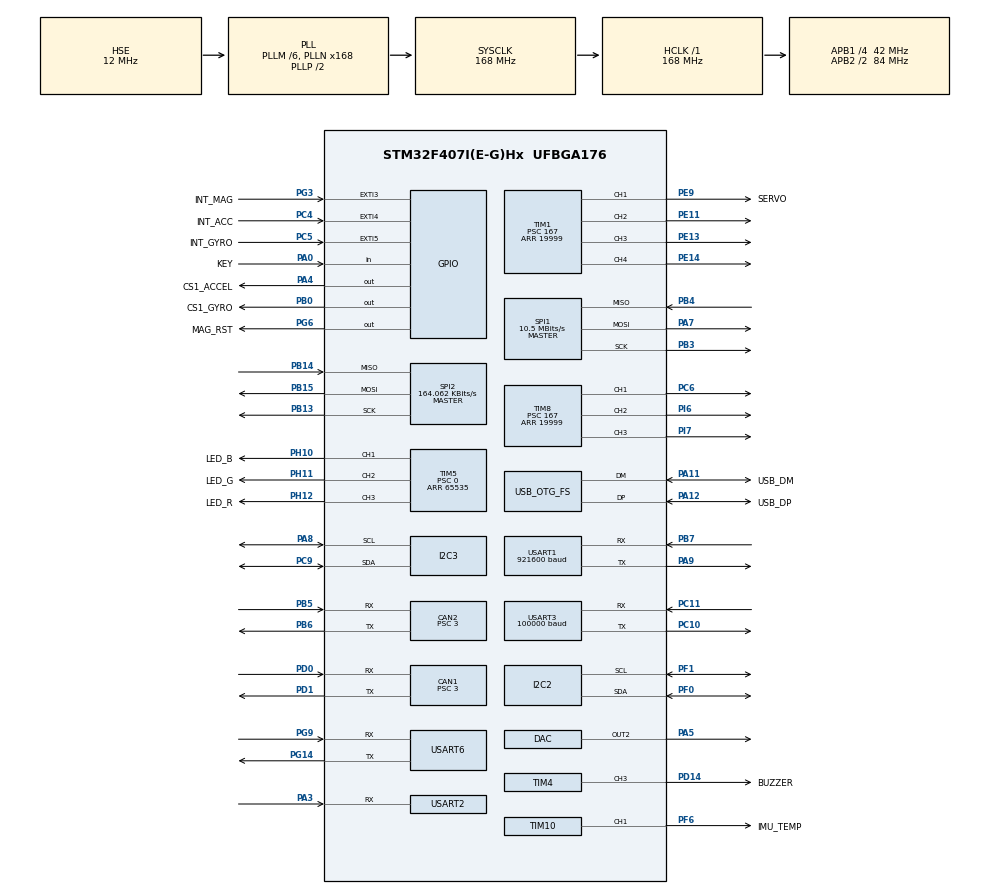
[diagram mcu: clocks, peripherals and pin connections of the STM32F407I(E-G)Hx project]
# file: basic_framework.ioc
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ADC1.Channel-0\#ChannelRegularConversion=ADC_CHANNEL_TEMPSENSOR
ADC1.ClockPrescaler=ADC_CLOCK_SYNC_PCLK_DIV6
ADC1.NbrOfConversionFlag=1
ADC1.Rank-0\#ChannelRegularConversion=1
ADC1.SamplingTime-0\#ChannelRegularConversion=ADC_SAMPLETIME_3CYCLES
ADC1.master=1
CAN1.BS1=CAN_BS1_10TQ
CAN1.BS2=CAN_BS2_3TQ
CAN1.CalculateBaudRate=1000000
CAN1.CalculateTimeBit=1000
CAN1.CalculateTimeQuantum=71.42857142857143
CAN1.NART=ENABLE
CAN1.Prescaler=3
CAN1.TXFP=ENABLE
CAN2.BS1=CAN_BS1_10TQ
CAN2.BS2=CAN_BS2_3TQ
CAN2.CalculateBaudRate=1000000
CAN2.CalculateTimeBit=1000
CAN2.CalculateTimeQuantum=71.42857142857143
CAN2.NART=ENABLE
CAN2.Prescaler=3
CAN2.TXFP=ENABLE
Dma.I2C2_RX.6.Direction=DMA_PERIPH_TO_MEMORY
Dma.I2C2_RX.6.FIFOMode=DMA_FIFOMODE_DISABLE
Dma.I2C2_RX.6.Instance=DMA1_Stream2
Dma.I2C2_RX.6.MemDataAlignment=DMA_MDATAALIGN_BYTE
Dma.I2C2_RX.6.MemInc=DMA_MINC_ENABLE
Dma.I2C2_RX.6.Mode=DMA_NORMAL
Dma.I2C2_RX.6.PeriphDataAlignment=DMA_PDATAALIGN_BYTE
Dma.I2C2_RX.6.PeriphInc=DMA_PINC_DISABLE
Dma.I2C2_RX.6.Priority=DMA_PRIORITY_LOW
Dma.I2C2_TX.7.Direction=DMA_MEMORY_TO_PERIPH
Dma.I2C2_TX.7.FIFOMode=DMA_FIFOMODE_DISABLE
Dma.I2C2_TX.7.Instance=DMA1_Stream7
Dma.I2C2_TX.7.MemDataAlignment=DMA_MDATAALIGN_BYTE
Dma.I2C2_TX.7.MemInc=DMA_MINC_ENABLE
Dma.I2C2_TX.7.Mode=DMA_NORMAL
Dma.I2C2_TX.7.PeriphDataAlignment=DMA_PDATAALIGN_BYTE
Dma.I2C2_TX.7.PeriphInc=DMA_PINC_DISABLE
Dma.I2C2_TX.7.Priority=DMA_PRIORITY_LOW
Dma.Request0=USART6_RX
Dma.Request1=USART6_TX
Dma.Request2=USART1_TX
Dma.Request3=USART1_RX
Dma.Request4=SPI1_RX
Dma.Request5=USART3_RX
Dma.Request6=I2C2_RX
Dma.Request7=I2C2_TX
Dma.Request8=SPI1_TX
Dma.Request9=USART2_RX
Dma.SPI1_RX.4.Direction=DMA_PERIPH_TO_MEMORY
Dma.SPI1_RX.4.FIFOMode=DMA_FIFOMODE_ENABLE
Dma.SPI1_RX.4.FIFOThreshold=DMA_FIFO_THRESHOLD_FULL
Dma.SPI1_RX.4.Instance=DMA2_Stream0
Dma.SPI1_RX.4.MemBurst=DMA_MBURST_SINGLE
Dma.SPI1_RX.4.MemDataAlignment=DMA_MDATAALIGN_BYTE
Dma.SPI1_RX.4.MemInc=DMA_MINC_ENABLE
Dma.SPI1_RX.4.Mode=DMA_NORMAL
Dma.SPI1_RX.4.PeriphBurst=DMA_PBURST_SINGLE
Dma.SPI1_RX.4.PeriphDataAlignment=DMA_PDATAALIGN_BYTE
Dma.SPI1_RX.4.PeriphInc=DMA_PINC_DISABLE
Dma.SPI1_RX.4.Priority=DMA_PRIORITY_HIGH
Dma.SPI1_TX.8.Direction=DMA_MEMORY_TO_PERIPH
Dma.SPI1_TX.8.FIFOMode=DMA_FIFOMODE_DISABLE
Dma.SPI1_TX.8.Instance=DMA2_Stream3
Dma.SPI1_TX.8.MemDataAlignment=DMA_MDATAALIGN_BYTE
Dma.SPI1_TX.8.MemInc=DMA_MINC_ENABLE
Dma.SPI1_TX.8.Mode=DMA_NORMAL
Dma.SPI1_TX.8.PeriphDataAlignment=DMA_PDATAALIGN_BYTE
Dma.SPI1_TX.8.PeriphInc=DMA_PINC_DISABLE
Dma.SPI1_TX.8.Priority=DMA_PRIORITY_HIGH
Dma.USART1_RX.3.Direction=DMA_PERIPH_TO_MEMORY
Dma.USART1_RX.3.FIFOMode=DMA_FIFOMODE_DISABLE
Dma.USART1_RX.3.Instance=DMA2_Stream5
Dma.USART1_RX.3.MemDataAlignment=DMA_MDATAALIGN_BYTE
Dma.USART1_RX.3.MemInc=DMA_MINC_ENABLE
Dma.USART1_RX.3.Mode=DMA_NORMAL
Dma.USART1_RX.3.PeriphDataAlignment=DMA_PDATAALIGN_BYTE
Dma.USART1_RX.3.PeriphInc=DMA_PINC_DISABLE
Dma.USART1_RX.3.Priority=DMA_PRIORITY_VERY_HIGH
Dma.USART1_TX.2.Direction=DMA_MEMORY_TO_PERIPH
Dma.USART1_TX.2.FIFOMode=DMA_FIFOMODE_DISABLE
Dma.USART1_TX.2.Instance=DMA2_Stream7
Dma.USART1_TX.2.MemDataAlignment=DMA_MDATAALIGN_BYTE
Dma.USART1_TX.2.MemInc=DMA_MINC_ENABLE
Dma.USART1_TX.2.Mode=DMA_NORMAL
Dma.USART1_TX.2.PeriphDataAlignment=DMA_PDATAALIGN_BYTE
Dma.USART1_TX.2.PeriphInc=DMA_PINC_DISABLE
Dma.USART1_TX.2.Priority=DMA_PRIORITY_VERY_HIGH
Dma.USART2_RX.9.Direction=DMA_PERIPH_TO_MEMORY
Dma.USART2_RX.9.FIFOMode=DMA_FIFOMODE_DISABLE
Dma.USART2_RX.9.Instance=DMA1_Stream5
Dma.USART2_RX.9.MemDataAlignment=DMA_MDATAALIGN_BYTE
Dma.USART2_RX.9.MemInc=DMA_MINC_ENABLE
Dma.USART2_RX.9.Mode=DMA_NORMAL
Dma.USART2_RX.9.PeriphDataAlignment=DMA_PDATAALIGN_BYTE
Dma.USART2_RX.9.PeriphInc=DMA_PINC_DISABLE
Dma.USART2_RX.9.Priority=DMA_PRIORITY_HIGH
Dma.USART3_RX.5.Direction=DMA_PERIPH_TO_MEMORY
Dma.USART3_RX.5.FIFOMode=DMA_FIFOMODE_DISABLE
Dma.USART3_RX.5.Instance=DMA1_Stream1
Dma.USART3_RX.5.MemDataAlignment=DMA_MDATAALIGN_BYTE
Dma.USART3_RX.5.MemInc=DMA_MINC_ENABLE
Dma.USART3_RX.5.Mode=DMA_NORMAL
Dma.USART3_RX.5.PeriphDataAlignment=DMA_PDATAALIGN_BYTE
Dma.USART3_RX.5.PeriphInc=DMA_PINC_DISABLE
Dma.USART3_RX.5.Priority=DMA_PRIORITY_LOW
Dma.USART6_RX.0.Direction=DMA_PERIPH_TO_MEMORY
Dma.USART6_RX.0.FIFOMode=DMA_FIFOMODE_ENABLE
Dma.USART6_RX.0.FIFOThreshold=DMA_FIFO_THRESHOLD_FULL
Dma.USART6_RX.0.Instance=DMA2_Stream2
Dma.USART6_RX.0.MemBurst=DMA_MBURST_SINGLE
Dma.USART6_RX.0.MemDataAlignment=DMA_MDATAALIGN_BYTE
Dma.USART6_RX.0.MemInc=DMA_MINC_ENABLE
Dma.USART6_RX.0.Mode=DMA_NORMAL
Dma.USART6_RX.0.PeriphBurst=DMA_PBURST_SINGLE
Dma.USART6_RX.0.PeriphDataAlignment=DMA_PDATAALIGN_BYTE
Dma.USART6_RX.0.PeriphInc=DMA_PINC_DISABLE
Dma.USART6_RX.0.Priority=DMA_PRIORITY_HIGH
Dma.USART6_TX.1.Direction=DMA_MEMORY_TO_PERIPH
Dma.USART6_TX.1.FIFOMode=DMA_FIFOMODE_ENABLE
Dma.USART6_TX.1.FIFOThreshold=DMA_FIFO_THRESHOLD_FULL
Dma.USART6_TX.1.Instance=DMA2_Stream6
Dma.USART6_TX.1.MemBurst=DMA_MBURST_SINGLE
Dma.USART6_TX.1.MemDataAlignment=DMA_MDATAALIGN_BYTE
Dma.USART6_TX.1.MemInc=DMA_MINC_ENABLE
Dma.USART6_TX.1.Mode=DMA_NORMAL
Dma.USART6_TX.1.PeriphBurst=DMA_PBURST_SINGLE
Dma.USART6_TX.1.PeriphDataAlignment=DMA_PDATAALIGN_BYTE
Dma.USART6_TX.1.PeriphInc=DMA_PINC_DISABLE
Dma.USART6_TX.1.Priority=DMA_PRIORITY_HIGH
FREERTOS.INCLUDE_vTaskDelayUntil=1
FREERTOS.Tasks01=defaultTask,0,128,StartDefaultTask,Default,NULL,Dynamic,NULL,NULL
FREERTOS.configENABLE_FPU=1
FREERTOS.configMAX_TASK_NAME_LEN=32
FREERTOS.configTOTAL_HEAP_SIZE=20000
FREERTOS.configUSE_COUNTING_SEMAPHORES=1
FREERTOS.configUSE_POSIX_ERRNO=0
FREERTOS.configUSE_TIMERS=0
I2C2.I2C_Mode=I2C_Fast
I2C3.I2C_Mode=I2C_Fast
Mcu.Family=STM32F4
Mcu.Name=STM32F407I(E-G)Hx
Mcu.Package=UFBGA176
NVIC.CAN1_RX0_IRQn=true\:5\:0\:true\:false\:true\:true\:true\:true\:true
NVIC.CAN1_RX1_IRQn=true\:5\:0\:false\:false\:true\:true\:true\:true\:true
NVIC.CAN2_RX0_IRQn=true\:5\:0\:true\:false\:true\:true\:true\:true\:true
NVIC.CAN2_RX1_IRQn=true\:5\:0\:false\:false\:true\:true\:true\:true\:true
NVIC.DMA1_Stream1_IRQn=true\:5\:0\:false\:false\:true\:true\:false\:true\:true
NVIC.DMA1_Stream2_IRQn=true\:5\:0\:false\:false\:true\:true\:false\:true\:true
NVIC.DMA1_Stream5_IRQn=true\:5\:0\:false\:false\:true\:true\:false\:true\:true
NVIC.DMA1_Stream7_IRQn=true\:5\:0\:false\:false\:true\:true\:false\:true\:true
NVIC.DMA2_Stream0_IRQn=true\:5\:0\:false\:false\:true\:false\:false\:true\:true
NVIC.DMA2_Stream2_IRQn=true\:5\:0\:false\:false\:true\:true\:false\:true\:true
NVIC.DMA2_Stream3_IRQn=true\:5\:0\:false\:false\:true\:false\:false\:true\:true
NVIC.DMA2_Stream5_IRQn=true\:5\:0\:false\:false\:true\:false\:false\:true\:true
NVIC.DMA2_Stream6_IRQn=true\:5\:0\:true\:false\:true\:true\:false\:true\:true
NVIC.DMA2_Stream7_IRQn=true\:5\:0\:true\:false\:true\:true\:false\:true\:true
NVIC.EXTI3_IRQn=true\:5\:0\:true\:false\:true\:true\:true\:true\:true
NVIC.EXTI4_IRQn=true\:5\:0\:false\:false\:true\:true\:true\:true\:true
NVIC.EXTI9_5_IRQn=true\:5\:0\:false\:false\:true\:true\:true\:true\:true
NVIC.FLASH_IRQn=true\:6\:0\:true\:false\:true\:true\:true\:true\:true
NVIC.I2C2_ER_IRQn=true\:5\:0\:false\:false\:true\:true\:true\:true\:true
NVIC.I2C2_EV_IRQn=true\:5\:0\:false\:false\:true\:true\:true\:true\:true
NVIC.I2C3_ER_IRQn=true\:5\:0\:false\:false\:true\:true\:true\:true\:true
NVIC.I2C3_EV_IRQn=true\:5\:0\:false\:false\:true\:true\:true\:true\:true
NVIC.OTG_FS_IRQn=true\:5\:0\:false\:false\:true\:true\:true\:true\:true
NVIC.PriorityGroup=NVIC_PRIORITYGROUP_4
NVIC.SPI1_IRQn=true\:5\:0\:false\:false\:true\:true\:true\:true\:true
NVIC.SPI2_IRQn=true\:5\:0\:false\:false\:true\:true\:true\:true\:true
NVIC.TIM8_TRG_COM_TIM14_IRQn=true\:15\:0\:false\:false\:true\:false\:false\:true\:true
NVIC.TimeBase=TIM8_TRG_COM_TIM14_IRQn
NVIC.TimeBaseIP=TIM14
NVIC.USART1_IRQn=true\:5\:0\:false\:false\:true\:true\:true\:true\:true
NVIC.USART2_IRQn=true\:5\:0\:false\:false\:true\:true\:true\:true\:true
NVIC.USART3_IRQn=true\:5\:0\:false\:false\:true\:true\:true\:true\:true
NVIC.USART6_IRQn=true\:5\:0\:false\:false\:true\:true\:true\:true\:true
PA0-WKUP.GPIO_Label=KEY
PA0-WKUP.GPIO_PuPd=GPIO_PULLUP
PA0-WKUP.Signal=GPIO_Input
PA11.GPIO_Label=USB_DM
PA11.Mode=Device_Only
PA11.Signal=USB_OTG_FS_DM
PA12.GPIO_Label=USB_DP
PA12.Mode=Device_Only
PA12.Signal=USB_OTG_FS_DP
PA13.Mode=Serial_Wire
PA13.Signal=SYS_JTMS-SWDIO
PA14.Mode=Serial_Wire
PA14.Signal=SYS_JTCK-SWCLK
PA4.GPIO_Label=CS1_ACCEL
PA4.GPIO_PuPd=GPIO_PULLUP
PA4.GPIO_Speed=GPIO_SPEED_FREQ_HIGH
PA4.PinState=GPIO_PIN_SET
PA4.Signal=GPIO_Output
PA5.Signal=COMP_DAC2_group
PA7.GPIO_PuPd=GPIO_PULLUP
PA7.Mode=Full_Duplex_Master
PA7.Signal=SPI1_MOSI
PA8.Mode=I2C
PA8.Signal=I2C3_SCL
PA9.Mode=Asynchronous
PA9.Signal=USART1_TX
PB0.GPIO_Label=CS1_GYRO
PB0.GPIO_PuPd=GPIO_PULLUP
PB0.GPIO_Speed=GPIO_SPEED_FREQ_HIGH
PB0.PinState=GPIO_PIN_SET
PB0.Signal=GPIO_Output
PB13.Mode=Full_Duplex_Master
PB13.Signal=SPI2_SCK
PB14.Mode=Full_Duplex_Master
PB14.Signal=SPI2_MISO
PB15.Mode=Full_Duplex_Master
PB15.Signal=SPI2_MOSI
PB3.GPIO_PuPd=GPIO_PULLUP
PB3.Mode=Full_Duplex_Master
PB3.Signal=SPI1_SCK
PB4.GPIO_PuPd=GPIO_PULLUP
PB4.Mode=Full_Duplex_Master
PB4.Signal=SPI1_MISO
PB5.Mode=CAN_Activate
PB5.Signal=CAN2_RX
PB6.Mode=CAN_Activate
PB6.Signal=CAN2_TX
PB7.Mode=Asynchronous
PB7.Signal=USART1_RX
PC10.Mode=Asynchronous
PC10.Signal=USART3_TX
PC11.Mode=Asynchronous
PC11.Signal=USART3_RX
PC4.GPIO_Label=INT_ACC
PC4.GPIO_ModeDefaultEXTI=GPIO_MODE_IT_FALLING
PC4.Signal=GPXTI4
PC5.GPIO_Label=INT_GYRO
PC5.GPIO_ModeDefaultEXTI=GPIO_MODE_IT_FALLING
PC5.Signal=GPXTI5
PC6.Signal=S_TIM8_CH1
PC9.Mode=I2C
PC9.Signal=I2C3_SDA
PD0.Mode=CAN_Activate
PD0.Signal=CAN1_RX
PD1.Mode=CAN_Activate
PD1.Signal=CAN1_TX
PD14.GPIO_Label=BUZZER
PD14.GPIO_PuPd=GPIO_PULLUP
PD14.GPIO_Speed=GPIO_SPEED_FREQ_VERY_HIGH
PD14.Signal=S_TIM4_CH3
PA3.Mode=Asynchronous
PA3.Signal=USART2_RX
PE11.Signal=S_TIM1_CH2
PE13.Signal=S_TIM1_CH3
PE14.Signal=S_TIM1_CH4
PE9.GPIO_Label=SERVO
PE9.Signal=S_TIM1_CH1
PF0.Mode=I2C
PF0.Signal=I2C2_SDA
PF1.Mode=I2C
PF1.Signal=I2C2_SCL
PF6.GPIO_Label=IMU_TEMP
PF6.GPIO_PuPd=GPIO_PULLUP
PF6.GPIO_Speed=GPIO_SPEED_FREQ_HIGH
PF6.Signal=S_TIM10_CH1
PG14.Mode=Asynchronous
PG14.Signal=USART6_TX
PG3.GPIO_Label=INT_MAG
PG3.GPIO_ModeDefaultEXTI=GPIO_MODE_IT_FALLING
PG3.GPIO_PuPd=GPIO_PULLUP
PG3.Signal=GPXTI3
PG6.GPIO_Label=MAG_RST
PG6.Signal=GPIO_Output
PG9.Mode=Asynchronous
PG9.Signal=USART6_RX
PH0-OSC_IN.Mode=HSE-External-Oscillator
PH0-OSC_IN.Signal=RCC_OSC_IN
PH1-OSC_OUT.Mode=HSE-External-Oscillator
PH1-OSC_OUT.Signal=RCC_OSC_OUT
PH10.GPIO_Label=LED_B
PH10.GPIO_PuPd=GPIO_PULLUP
PH10.GPIO_Speed=GPIO_SPEED_FREQ_HIGH
PH10.Signal=S_TIM5_CH1
PH11.GPIO_Label=LED_G
PH11.GPIO_PuPd=GPIO_PULLUP
PH11.GPIO_Speed=GPIO_SPEED_FREQ_HIGH
PH11.Signal=S_TIM5_CH2
PH12.GPIO_Label=LED_R
PH12.GPIO_PuPd=GPIO_PULLUP
PH12.GPIO_Speed=GPIO_SPEED_FREQ_HIGH
PH12.Signal=S_TIM5_CH3
PI6.Signal=S_TIM8_CH2
PI7.Signal=S_TIM8_CH3
ProjectManager.HeapSize=0x5000
ProjectManager.StackSize=0x5000
ProjectManager.TargetToolchain=CMake
RCC.48MHZClocksFreq_Value=48000000
RCC.AHBFreq_Value=168000000
RCC.APB1CLKDivider=RCC_HCLK_DIV4
RCC.APB1Freq_Value=42000000
RCC.APB1TimFreq_Value=84000000
RCC.APB2CLKDivider=RCC_HCLK_DIV2
RCC.APB2Freq_Value=84000000
RCC.APB2TimFreq_Value=168000000
RCC.CortexFreq_Value=168000000
RCC.HCLKFreq_Value=168000000
RCC.HSE_VALUE=12000000
RCC.HSI_VALUE=16000000
RCC.LSE_VALUE=32768
RCC.PLLM=6
RCC.PLLN=168
RCC.PLLQ=7
RCC.RCC_RTC_Clock_SourceVirtual=RCC_RTCCLKSOURCE_HSE_DIV30
RCC.RCC_RTC_Clock_Source_FROM_HSE=RCC_RTCCLKSOURCE_HSE_DIV30
RCC.SYSCLKFreq_VALUE=168000000
RCC.SYSCLKSource=RCC_SYSCLKSOURCE_PLLCLK
RCC.VCOOutputFreq_Value=336000000
RTC.AsynchPrediv=124
RTC.SynchPrediv=3199
SH.COMP_DAC2_group.0=DAC_OUT2,DAC_OUT2
SH.S_TIM10_CH1.0=TIM10_CH1,PWM Generation1 CH1
SH.S_TIM1_CH1.0=TIM1_CH1,PWM Generation1 CH1
SH.S_TIM1_CH2.0=TIM1_CH2,PWM Generation2 CH2
SH.S_TIM1_CH3.0=TIM1_CH3,PWM Generation3 CH3
SH.S_TIM1_CH4.0=TIM1_CH4,PWM Generation4 CH4
SH.S_TIM4_CH3.0=TIM4_CH3,PWM Generation3 CH3
SH.S_TIM5_CH1.0=TIM5_CH1,PWM Generation1 CH1
SH.S_TIM5_CH2.0=TIM5_CH2,PWM Generation2 CH2
SH.S_TIM5_CH3.0=TIM5_CH3,PWM Generation3 CH3
SH.S_TIM8_CH1.0=TIM8_CH1,Output Compare1 CH1
SH.S_TIM8_CH2.0=TIM8_CH2,Output Compare2 CH2
SH.S_TIM8_CH3.0=TIM8_CH3,Output Compare3 CH3
SPI1.BaudRatePrescaler=SPI_BAUDRATEPRESCALER_8
SPI1.CLKPhase=SPI_PHASE_2EDGE
SPI1.CLKPolarity=SPI_POLARITY_HIGH
SPI1.CalculateBaudRate=10.5 MBits/s
SPI1.Direction=SPI_DIRECTION_2LINES
SPI1.Mode=SPI_MODE_MASTER
SPI1.VirtualType=VM_MASTER
SPI2.BaudRatePrescaler=SPI_BAUDRATEPRESCALER_256
SPI2.CLKPhase=SPI_PHASE_2EDGE
SPI2.CLKPolarity=SPI_POLARITY_HIGH
SPI2.CalculateBaudRate=164.062 KBits/s
SPI2.Direction=SPI_DIRECTION_2LINES
SPI2.Mode=SPI_MODE_MASTER
SPI2.VirtualType=VM_MASTER
TIM1.Channel-PWM\ Generation1\ CH1=TIM_CHANNEL_1
TIM1.Channel-PWM\ Generation2\ CH2=TIM_CHANNEL_2
TIM1.Channel-PWM\ Generation3\ CH3=TIM_CHANNEL_3
TIM1.Channel-PWM\ Generation4\ CH4=TIM_CHANNEL_4
TIM1.Period=19999
TIM1.Prescaler=167
TIM10.Channel=TIM_CHANNEL_1
TIM10.Period=5000-1
TIM10.Prescaler=167
TIM4.Channel-PWM\ Generation3\ CH3=TIM_CHANNEL_3
TIM4.Period=65535
TIM4.Prescaler=167
TIM5.Channel-PWM\ Generation1\ CH1=TIM_CHANNEL_1
TIM5.Channel-PWM\ Generation2\ CH2=TIM_CHANNEL_2
TIM5.Channel-PWM\ Generation3\ CH3=TIM_CHANNEL_3
TIM5.Period=65535
TIM5.Prescaler=0
TIM8.Channel-Output\ Compare1\ CH1=TIM_CHANNEL_1
TIM8.Channel-Output\ Compare2\ CH2=TIM_CHANNEL_2
TIM8.Channel-Output\ Compare3\ CH3=TIM_CHANNEL_3
TIM8.Period=19999
TIM8.Prescaler=167
USART1.BaudRate=921600
USART1.VirtualMode=VM_ASYNC
USART2.BaudRate=921600
USART2.VirtualMode=VM_ASYNC
USART3.BaudRate=100000
USART3.Parity=PARITY_EVEN
USART3.VirtualMode=VM_ASYNC
USART3.WordLength=WORDLENGTH_9B
USART6.VirtualMode=VM_ASYNC
USB_OTG_FS.VirtualMode=Device_Only
VP_ADC1_TempSens_Input.Mode=IN-TempSens
VP_ADC1_Vref_Input.Mode=IN-Vrefint
VP_CRC_VS_CRC.Mode=CRC_Activate
VP_FREERTOS_VS_CMSIS_V2.Mode=CMSIS_V2
VP_RNG_VS_RNG.Mode=RNG_Activate
VP_RTC_VS_RTC_Activate.Mode=RTC_Enabled
VP_SYS_VS_tim14.Mode=TIM14
VP_TIM10_VS_ClockSourceINT.Mode=Enable_Timer
VP_TIM1_VS_ClockSourceINT.Mode=Internal
VP_TIM4_VS_ClockSourceINT.Mode=Internal
VP_TIM5_VS_ClockSourceINT.Mode=Internal
VP_TIM8_VS_ClockSourceINT.Mode=Internal
board=custom

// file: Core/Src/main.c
/* USER CODE BEGIN Header */
/**
  ******************************************************************************
  * @file           : main.c
  * @brief          : Main program body
  ******************************************************************************
  * @attention
  *
  * Copyright (c) 2026 STMicroelectronics.
  * All rights reserved.
  *
  * This software is licensed under terms that can be found in the LICENSE file
  * in the root directory of this software component.
  * If no LICENSE file comes with this software, it is provided AS-IS.
  *
  ******************************************************************************
  */
/* USER CODE END Header */
#include "main.h"
#include "cmsis_os.h"
#include "adc.h"
#include "can.h"
#include "crc.h"
#include "dac.h"
#include "dma.h"
#include "i2c.h"
#include "rng.h"
#include "rtc.h"
#include "spi.h"
#include "tim.h"
#include "usart.h"
#include "usb_otg.h"
#include "gpio.h"

void SystemClock_Config(void);
void MX_FREERTOS_Init(void);

int main(void)
{

  /* MCU Configuration--------------------------------------------------------*/

  /* Reset of all peripherals, Initializes the Flash interface and the Systick. */
  HAL_Init();

  /* Configure the system clock */
  SystemClock_Config();

  /* Initialize all configured peripherals */
  MX_GPIO_Init();
  MX_DMA_Init();
  MX_ADC1_Init();
  MX_CAN1_Init();
  MX_CAN2_Init();
  MX_SPI1_Init();
  MX_TIM4_Init();
  MX_TIM5_Init();
  MX_USART3_UART_Init();
  MX_RNG_Init();
  MX_RTC_Init();
  MX_TIM1_Init();
  MX_TIM10_Init();
  MX_USART1_UART_Init();
  MX_USART2_UART_Init();
  MX_USART6_UART_Init();
  MX_TIM8_Init();
  MX_I2C2_Init();
  MX_I2C3_Init();
  MX_SPI2_Init();
  MX_CRC_Init();
  MX_DAC_Init();
  MX_USB_OTG_FS_PCD_Init();

  /* Init scheduler */
  osKernelInitialize();  /* Call init function for freertos objects (in cmsis_os2.c) */
  MX_FREERTOS_Init();

  /* Start scheduler */
  osKernelStart();

  /* We should never get here as control is now taken by the scheduler */

  /* Infinite loop */
  while (1)
  {

  }
}

void SystemClock_Config(void)
{
  RCC_OscInitTypeDef RCC_OscInitStruct = {0};
  RCC_ClkInitTypeDef RCC_ClkInitStruct = {0};

  /** Configure the main internal regulator output voltage
  */
  __HAL_RCC_PWR_CLK_ENABLE();
  __HAL_PWR_VOLTAGESCALING_CONFIG(PWR_REGULATOR_VOLTAGE_SCALE1);

  /** Initializes the RCC Oscillators according to the specified parameters
  * in the RCC_OscInitTypeDef structure.
  */
  RCC_OscInitStruct.OscillatorType = RCC_OSCILLATORTYPE_HSE;
  RCC_OscInitStruct.HSEState = RCC_HSE_ON;
  RCC_OscInitStruct.PLL.PLLState = RCC_PLL_ON;
  RCC_OscInitStruct.PLL.PLLSource = RCC_PLLSOURCE_HSE;
  RCC_OscInitStruct.PLL.PLLM = 6;
  RCC_OscInitStruct.PLL.PLLN = 168;
  RCC_OscInitStruct.PLL.PLLP = RCC_PLLP_DIV2;
  RCC_OscInitStruct.PLL.PLLQ = 7;
  if (HAL_RCC_OscConfig(&RCC_OscInitStruct) != HAL_OK)
  {
    Error_Handler();
  }

  /** Initializes the CPU, AHB and APB buses clocks
  */
  RCC_ClkInitStruct.ClockType = RCC_CLOCKTYPE_HCLK|RCC_CLOCKTYPE_SYSCLK
                              |RCC_CLOCKTYPE_PCLK1|RCC_CLOCKTYPE_PCLK2;
  RCC_ClkInitStruct.SYSCLKSource = RCC_SYSCLKSOURCE_PLLCLK;
  RCC_ClkInitStruct.AHBCLKDivider = RCC_SYSCLK_DIV1;
  RCC_ClkInitStruct.APB1CLKDivider = RCC_HCLK_DIV4;
  RCC_ClkInitStruct.APB2CLKDivider = RCC_HCLK_DIV2;

  if (HAL_RCC_ClockConfig(&RCC_ClkInitStruct, FLASH_LATENCY_5) != HAL_OK)
  {
    Error_Handler();
  }
}

void HAL_TIM_PeriodElapsedCallback(TIM_HandleTypeDef *htim)
{
  if (htim->Instance == TIM14)
  {
    HAL_IncTick();
  }
}

void Error_Handler(void)
{
  __disable_irq();
  while (1)
  {
  }
}

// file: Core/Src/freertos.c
/* USER CODE BEGIN Header */
/**
  ******************************************************************************
  * File Name          : freertos.c
  * Description        : Code for freertos applications
  ******************************************************************************
  * @attention
  *
  * Copyright (c) 2026 STMicroelectronics.
  * All rights reserved.
  *
  * This software is licensed under terms that can be found in the LICENSE file
  * in the root directory of this software component.
  * If no LICENSE file comes with this software, it is provided AS-IS.
  *
  ******************************************************************************
  */
/* USER CODE END Header */

#include "FreeRTOS.h"
#include "task.h"
#include "main.h"
#include "cmsis_os.h"

/* USER CODE BEGIN Includes */
#include "app_main.h"

/* USER CODE END Includes */

/* Definitions for defaultTask */
osThreadId_t defaultTaskHandle;
const osThreadAttr_t defaultTask_attributes = {
  .name = "defaultTask",
  .stack_size = 128 * 96,
  .priority = (osPriority_t) osPriorityNormal,
};

void StartDefaultTask(void *argument);

void MX_FREERTOS_Init(void); /* (MISRA C 2004 rule 8.1) */

void MX_FREERTOS_Init(void) {

  /* Create the thread(s) */
  /* creation of defaultTask */
  defaultTaskHandle = osThreadNew(StartDefaultTask, NULL, &defaultTask_attributes);

}

void StartDefaultTask(void *argument)
{
  /* USER CODE BEGIN StartDefaultTask */
  (void)argument;
  app_main();
  vTaskDelete(NULL);
  /* USER CODE END StartDefaultTask */
}

/* USER CODE BEGIN Application */

void vApplicationMallocFailedHook(void)
{
  /* 堆分配失败时停在这里，便于 J-Link/GDB 直接定位内存水位问题。 */
  taskDISABLE_INTERRUPTS();
  for (;;) {
  }
}

/* USER CODE END Application */
